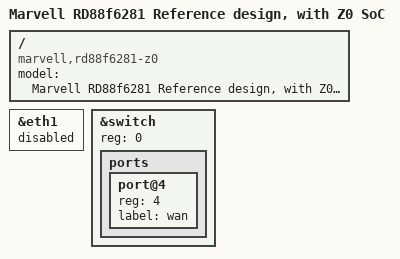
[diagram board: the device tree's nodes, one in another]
/dts-v1/;
#include "kirkwood-rd88f6281.dtsi"
/ {
	model = "Marvell RD88f6281 Reference design, with Z0 SoC";
	compatible = "marvell,rd88f6281-z0", "marvell,rd88f6281","marvell,kirkwood-88f6281", "marvell,kirkwood";
};
&eth1 {
	status = "disabled";
};
&switch {
	reg = <0>;
	ports {
		port@4 {
			reg = <4>;
			label = "wan";
		};
	};
};
